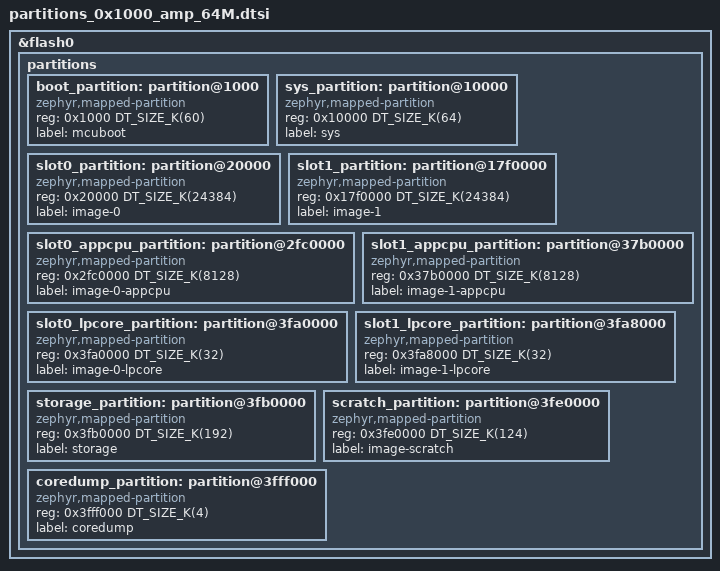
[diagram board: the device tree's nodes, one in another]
/*
 * Copyright (c) 2024-2025 Espressif Systems (Shanghai) Co., Ltd.
 *
 * SPDX-License-Identifier: Apache-2.0
 */

&flash0 {
	partitions {
		ranges;
		#address-cells = <1>;
		#size-cells = <1>;

		boot_partition: partition@1000 {
			compatible = "zephyr,mapped-partition";
			reg = <0x1000 DT_SIZE_K(60)>;
			label = "mcuboot";
		};

		sys_partition: partition@10000 {
			compatible = "zephyr,mapped-partition";
			reg = <0x10000 DT_SIZE_K(64)>;
			label = "sys";
		};

		slot0_partition: partition@20000 {
			compatible = "zephyr,mapped-partition";
			reg = <0x20000 DT_SIZE_K(24384)>;
			label = "image-0";
		};

		slot1_partition: partition@17f0000 {
			compatible = "zephyr,mapped-partition";
			reg = <0x17f0000 DT_SIZE_K(24384)>;
			label = "image-1";
		};

		slot0_appcpu_partition: partition@2fc0000 {
			compatible = "zephyr,mapped-partition";
			reg = <0x2fc0000 DT_SIZE_K(8128)>;
			label = "image-0-appcpu";
		};

		slot1_appcpu_partition: partition@37b0000 {
			compatible = "zephyr,mapped-partition";
			reg = <0x37b0000 DT_SIZE_K(8128)>;
			label = "image-1-appcpu";
		};

		slot0_lpcore_partition: partition@3fa0000 {
			compatible = "zephyr,mapped-partition";
			reg = <0x3fa0000 DT_SIZE_K(32)>;
			label = "image-0-lpcore";
		};

		slot1_lpcore_partition: partition@3fa8000 {
			compatible = "zephyr,mapped-partition";
			reg = <0x3fa8000 DT_SIZE_K(32)>;
			label = "image-1-lpcore";
		};

		storage_partition: partition@3fb0000 {
			compatible = "zephyr,mapped-partition";
			reg = <0x3fb0000 DT_SIZE_K(192)>;
			label = "storage";
		};

		scratch_partition: partition@3fe0000 {
			compatible = "zephyr,mapped-partition";
			reg = <0x3fe0000 DT_SIZE_K(124)>;
			label = "image-scratch";
		};

		coredump_partition: partition@3fff000 {
			compatible = "zephyr,mapped-partition";
			reg = <0x3fff000 DT_SIZE_K(4)>;
			label = "coredump";
		};
	};
};

/* Remaining flash size is 0kB
 * Last used address is 0x3FFFFFF
 */
